# STM32L081KZU6 register map
File version: 1.0
Registers are 32-bit, access not given, reset 0x0 unless marked. A register's access mark holds for its fields unless they carry their own. Offsets are from the block's base; [hi:lo] are bit positions; {n}, {i} and the like mark numbered series.

## DMA1_CSELR
Base 0x400200A8
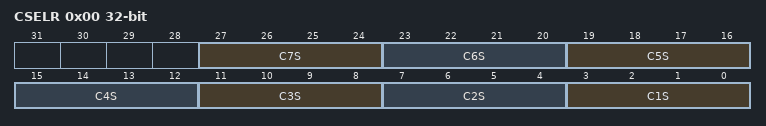
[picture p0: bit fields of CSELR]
0x00 CSELR
  [4n-1:4n-4] C{n}S (n=1..7)

## RCC
Base 0x40021000
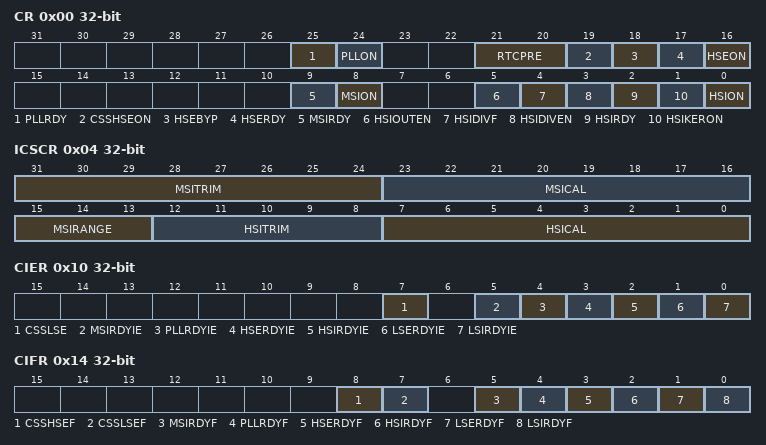
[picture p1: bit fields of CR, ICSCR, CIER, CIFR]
0x00 CR
  [25] PLLRDY, [24] PLLON, [21:20] RTCPRE, [19] CSSHSEON, [18] HSEBYP, [17] HSERDY, [16] HSEON, [9] MSIRDY, [8] MSION, [5] HSIOUTEN, [4] HSIDIVF, [3] HSIDIVEN, [2] HSIRDY, [1] HSIKERON, [0] HSION
0x04 ICSCR
  [31:24] MSITRIM, [23:16] MSICAL, [15:13] MSIRANGE, [12:8] HSITRIM, [7:0] HSICAL
0x08 CRRCR
0x0C CFGR
  [30:28] MCOPRE, [26] MCOSEL_HSE, [26:25] MCOSEL_LSI, [24] MCOSEL_SYSCLK, [23] PLLDIV3, [23:22] PLLDIV4, [21:18] PLLMUL, [16] PLLSRC, [15] STOPWUCK, [13:11] PPRE2, [10:8] PPRE1, [7:4] HPRE, [3:2] SWS, [1:0] SW
0x10 CIER
  [7] CSSLSE, [5] MSIRDYIE, [4] PLLRDYIE, [3] HSERDYIE, [2] HSIRDYIE, [1] LSERDYIE, [0] LSIRDYIE
0x14 CIFR
  [8] CSSHSEF, [7] CSSLSEF, [5] MSIRDYF, [4] PLLRDYF, [3] HSERDYF, [2] HSIRDYF, [1] LSERDYF, [0] LSIRDYF
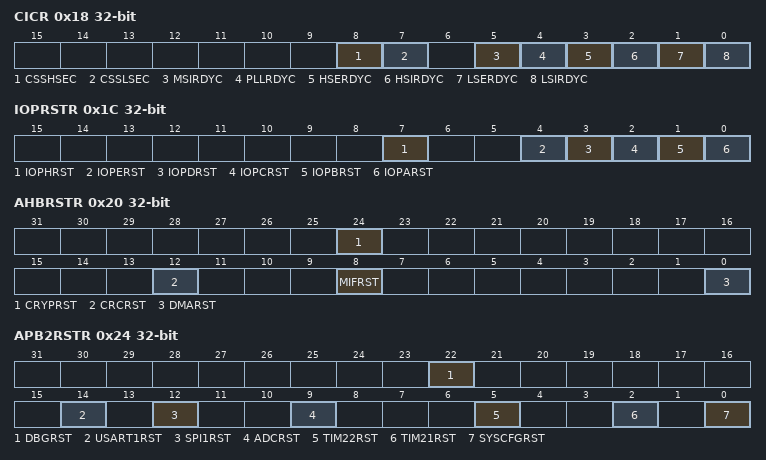
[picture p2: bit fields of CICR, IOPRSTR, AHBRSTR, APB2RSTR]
0x18 CICR
  [8] CSSHSEC, [7] CSSLSEC, [5] MSIRDYC, [4] PLLRDYC, [3] HSERDYC, [2] HSIRDYC, [1] LSERDYC, [0] LSIRDYC
0x1C IOPRSTR
  [7] IOPHRST, [4] IOPERST, [3] IOPDRST, [2] IOPCRST, [1] IOPBRST, [0] IOPARST
0x20 AHBRSTR
  [24] CRYPRST, [12] CRCRST, [8] MIFRST, [0] DMARST
0x24 APB2RSTR
  [22] DBGRST, [14] USART1RST, [12] SPI1RST, [9] ADCRST, [5] TIM22RST, [2] TIM21RST, [0] SYSCFGRST
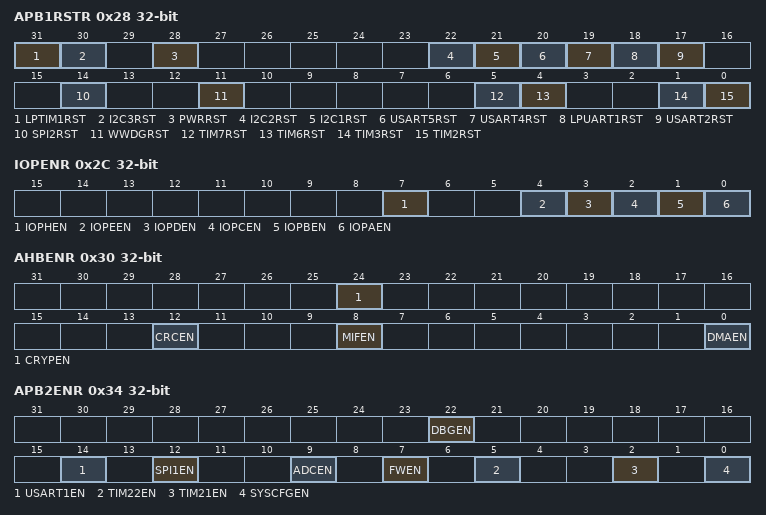
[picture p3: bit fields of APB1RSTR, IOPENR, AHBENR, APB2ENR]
0x28 APB1RSTR
  [31] LPTIM1RST, [30] I2C3RST, [28] PWRRST, [22] I2C2RST, [21] I2C1RST, [20] USART5RST, [19] USART4RST, [18] LPUART1RST, [17] USART2RST, [14] SPI2RST, [11] WWDGRST, [5] TIM7RST, [4] TIM6RST, [1] TIM3RST, [0] TIM2RST
0x2C IOPENR
  [7] IOPHEN, [4] IOPEEN, [3] IOPDEN, [2] IOPCEN, [1] IOPBEN, [0] IOPAEN
0x30 AHBENR
  [24] CRYPEN, [12] CRCEN, [8] MIFEN, [0] DMAEN
0x34 APB2ENR
  [22] DBGEN, [14] USART1EN, [12] SPI1EN, [9] ADCEN, [7] FWEN, [5] TIM22EN, [2] TIM21EN, [0] SYSCFGEN
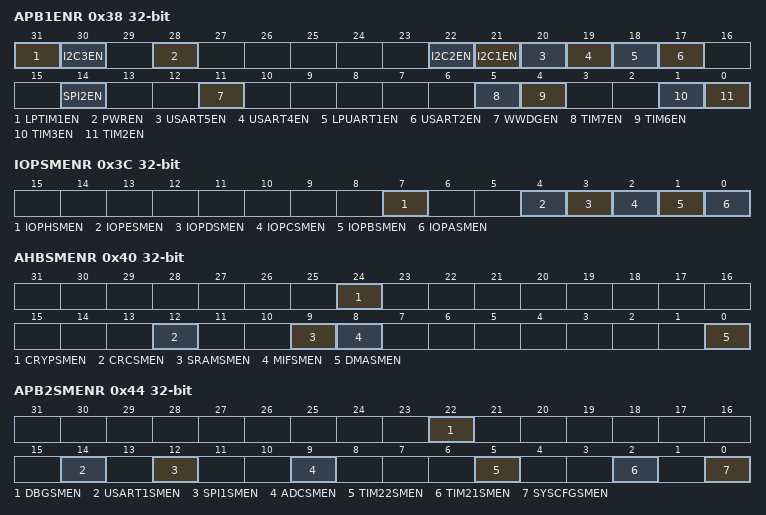
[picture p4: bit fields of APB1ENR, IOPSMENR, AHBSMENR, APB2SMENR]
0x38 APB1ENR
  [31] LPTIM1EN, [30] I2C3EN, [28] PWREN, [22] I2C2EN, [21] I2C1EN, [20] USART5EN, [19] USART4EN, [18] LPUART1EN, [17] USART2EN, [14] SPI2EN, [11] WWDGEN, [5] TIM7EN, [4] TIM6EN, [1] TIM3EN, [0] TIM2EN
0x3C IOPSMENR
  [7] IOPHSMEN, [4] IOPESMEN, [3] IOPDSMEN, [2] IOPCSMEN, [1] IOPBSMEN, [0] IOPASMEN
0x40 AHBSMENR
  [24] CRYPSMEN, [12] CRCSMEN, [9] SRAMSMEN, [8] MIFSMEN, [0] DMASMEN
0x44 APB2SMENR
  [22] DBGSMEN, [14] USART1SMEN, [12] SPI1SMEN, [9] ADCSMEN, [5] TIM22SMEN, [2] TIM21SMEN, [0] SYSCFGSMEN
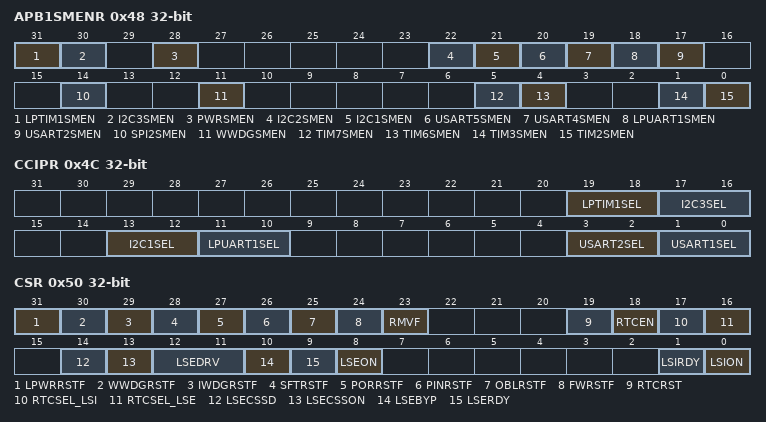
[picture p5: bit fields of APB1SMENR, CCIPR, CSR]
0x48 APB1SMENR
  [31] LPTIM1SMEN, [30] I2C3SMEN, [28] PWRSMEN, [22] I2C2SMEN, [21] I2C1SMEN, [20] USART5SMEN, [19] USART4SMEN, [18] LPUART1SMEN, [17] USART2SMEN, [14] SPI2SMEN, [11] WWDGSMEN, [5] TIM7SMEN, [4] TIM6SMEN, [1] TIM3SMEN, [0] TIM2SMEN
0x4C CCIPR
  [19:18] LPTIM1SEL, [17:16] I2C3SEL, [13:12] I2C1SEL, [11:10] LPUART1SEL, [3:2] USART2SEL, [1:0] USART1SEL
0x50 CSR
  [31] LPWRRSTF, [30] WWDGRSTF, [29] IWDGRSTF, [28] SFTRSTF, [27] PORRSTF, [26] PINRSTF, [25] OBLRSTF, [24] FWRSTF, [23] RMVF, [19] RTCRST, [18] RTCEN, [17] RTCSEL_LSI, [16] RTCSEL_LSE, [14] LSECSSD, [13] LSECSSON, [12:11] LSEDRV, [10] LSEBYP, [9] LSERDY, [8] LSEON, [1] LSIRDY, [0] LSION

## FLASH
Base 0x40022000
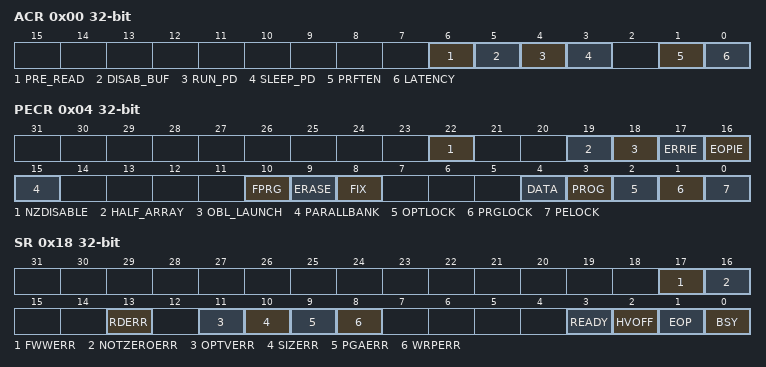
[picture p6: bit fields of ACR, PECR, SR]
0x00 ACR
  [6] PRE_READ, [5] DISAB_BUF, [4] RUN_PD, [3] SLEEP_PD, [1] PRFTEN, [0] LATENCY
0x04 PECR
  [22] NZDISABLE, [19] HALF_ARRAY, [18] OBL_LAUNCH, [17] ERRIE, [16] EOPIE, [15] PARALLBANK, [10] FPRG, [9] ERASE, [8] FIX, [4] DATA, [3] PROG, [2] OPTLOCK, [1] PRGLOCK, [0] PELOCK
0x08 PDKEYR
0x0C PEKEYR
0x10 PRGKEYR
0x14 OPTKEYR
0x18 SR
  [17] FWWERR, [16] NOTZEROERR, [13] RDERR, [11] OPTVERR, [10] SIZERR, [9] PGAERR, [8] WRPERR, [3] READY, [2] HVOFF, [1] EOP, [0] BSY
0x1C OPTR
  [31] BOOT1, [23] BFB2, [22] nRST_STDBY, [21] nRST_STOP, [22:20] USER, [19:16] BOR_LEV, [8] WPRMOD, [7:0] RDPROT
0x20 WRPR
  [15:0] WRP
0x80 WRPR2

## CRC
Base 0x40023000
0x00 DR
0x04 IDR 8-bit
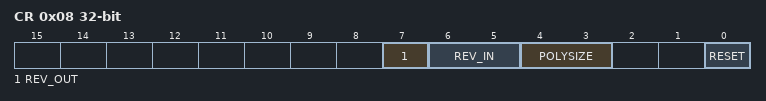
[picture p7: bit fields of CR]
0x08 CR
  [7] REV_OUT, [6:5] REV_IN, [4:3] POLYSIZE, [0] RESET
0x10 INIT
0x14 POL

## AES
Base 0x40026000
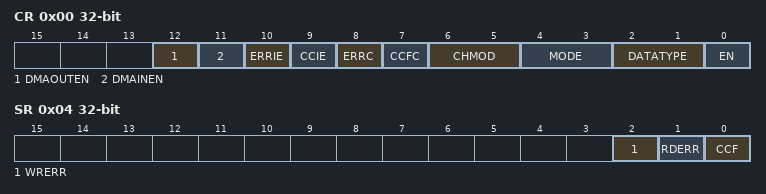
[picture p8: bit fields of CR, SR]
0x00 CR
  [12] DMAOUTEN, [11] DMAINEN, [10] ERRIE, [9] CCIE, [8] ERRC, [7] CCFC, [6:5] CHMOD, [4:3] MODE, [2:1] DATATYPE, [0] EN
0x04 SR
  [2] WRERR, [1] RDERR, [0] CCF
0x08 DINR
0x0C DOUTR
{0x10+4i} KEYR{i} (i=0..3)
{0x20+4i} IVR{i} (i=0..3)

## GPIOA
Base 0x50000000
Same registers: GPIOB 0x50000400, GPIOC 0x50000800, GPIOD 0x50000C00, GPIOE 0x50001000, GPIOH 0x50001C00
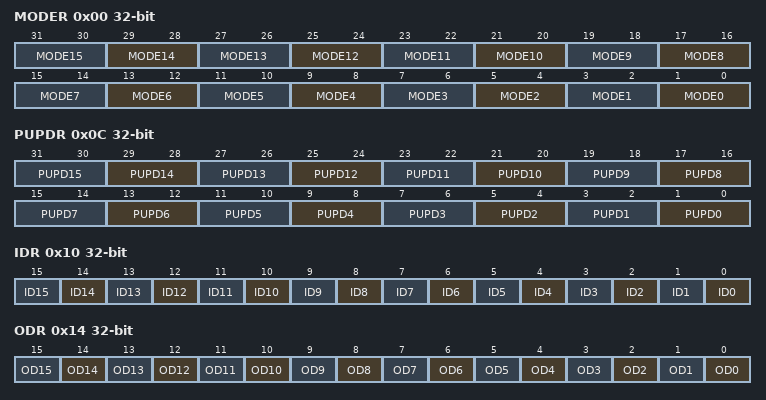
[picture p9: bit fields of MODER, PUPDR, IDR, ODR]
0x00 MODER
  [2n+1:2n] MODE{n} (n=0..15)
0x04 OTYPER
0x08 OSPEEDR
0x0C PUPDR
  [2n+1:2n] PUPD{n} (n=0..15)
0x10 IDR
  [n] ID{n} (n=0..15)
0x14 ODR
  [n] OD{n} (n=0..15)
0x18 BSRR
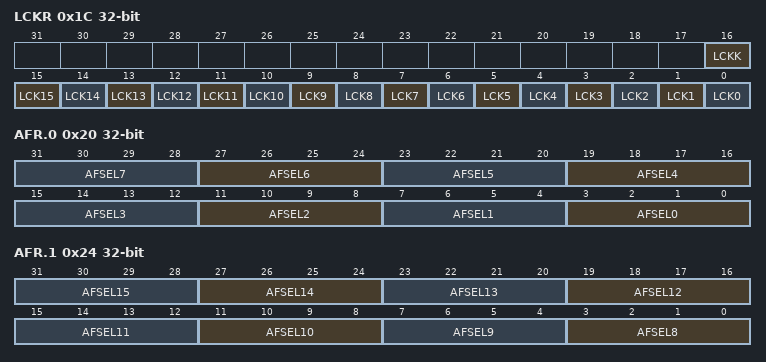
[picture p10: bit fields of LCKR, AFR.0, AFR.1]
0x1C LCKR
  [16] LCKK, [n] LCK{n} (n=0..15)
0x20 AFR.0
  [4n+3:4n] AFSEL{n} (n=0..7)
0x24 AFR.1
  [4n-29:4n-32] AFSEL{n} (n=8..15)
0x28 BRR
